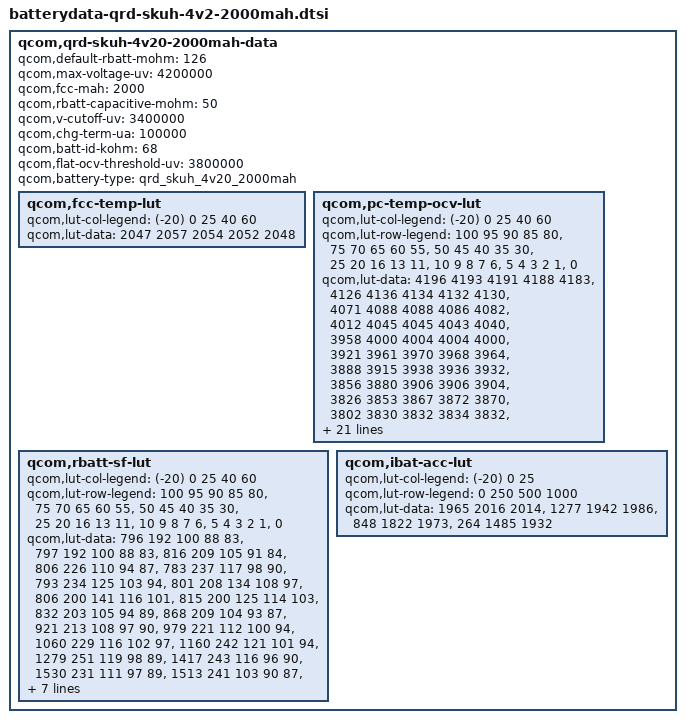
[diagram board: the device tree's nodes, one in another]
/* Copyright (c) 2014, The Linux Foundation. All rights reserved.
 *
 * This program is free software; you can redistribute it and/or modify
 * it under the terms of the GNU General Public License version 2 and
 * only version 2 as published by the Free Software Foundation.
 *
 * This program is distributed in the hope that it will be useful,
 * but WITHOUT ANY WARRANTY; without even the implied warranty of
 * MERCHANTABILITY or FITNESS FOR A PARTICULAR PURPOSE.  See the
 * GNU General Public License for more details.
 */

qcom,qrd-skuh-4v20-2000mah-data {
	qcom,default-rbatt-mohm = <126>;
	qcom,max-voltage-uv = <4200000>;
	qcom,fcc-mah = <2000>;
	qcom,rbatt-capacitive-mohm = <50>;
	qcom,v-cutoff-uv = <3400000>;
	qcom,chg-term-ua = <100000>;
	qcom,batt-id-kohm = <68>;
	qcom,flat-ocv-threshold-uv = <3800000>;
	qcom,battery-type = "qrd_skuh_4v20_2000mah";

	qcom,fcc-temp-lut {
		qcom,lut-col-legend = <(-20) 0 25 40 60>;
		qcom,lut-data = <2047 2057 2054 2052 2048>;
	};

	qcom,pc-temp-ocv-lut {
		qcom,lut-col-legend = <(-20) 0 25 40 60>;
		qcom,lut-row-legend = <100 95 90 85 80>,
				<75 70 65 60 55>,
				<50 45 40 35 30>,
				<25 20 16 13 11>,
				<10 9 8 7 6>,
				<5 4 3 2 1>,
				<0>;
		qcom,lut-data = <4196 4193 4191 4188 4183>,
				<4126 4136 4134 4132 4130>,
				<4071 4088 4088 4086 4082>,
				<4012 4045 4045 4043 4040>,
				<3958 4000 4004 4004 4000>,
				<3921 3961 3970 3968 3964>,
				<3888 3915 3938 3936 3932>,
				<3856 3880 3906 3906 3904>,
				<3826 3853 3867 3872 3870>,
				<3802 3830 3832 3834 3832>,
				<3784 3811 3812 3812 3810>,
				<3771 3795 3796 3796 3794>,
				<3758 3782 3783 3782 3780>,
				<3746 3773 3773 3771 3768>,
				<3734 3766 3766 3760 3752>,
				<3722 3752 3755 3746 3732>,
				<3708 3729 3734 3724 3710>,
				<3692 3706 3705 3696 3683>,
				<3675 3696 3684 3676 3664>,
				<3658 3691 3681 3673 3661>,
				<3645 3688 3679 3672 3660>,
				<3626 3685 3678 3670 3658>,
				<3603 3681 3675 3668 3655>,
				<3574 3676 3672 3662 3650>,
				<3534 3664 3662 3651 3637>,
				<3476 3638 3636 3622 3604>,
				<3398 3593 3589 3574 3552>,
				<3304 3528 3525 3510 3488>,
				<3230 3436 3439 3424 3400>,
				<3168 3295 3310 3292 3260>,
				<3000 3015 3000 3000 3000>;
	};

	qcom,rbatt-sf-lut {
		qcom,lut-col-legend = <(-20) 0 25 40 60>;
		qcom,lut-row-legend = <100 95 90 85 80>,
				<75 70 65 60 55>,
				<50 45 40 35 30>,
				<25 20 16 13 11>,
				<10 9 8 7 6>,
				<5 4 3 2 1>,
				<0>;
		qcom,lut-data = <796 192 100 88 83>,
				<797 192 100 88 83>,
				<816 209 105 91 84>,
				<806 226 110 94 87>,
				<783 237 117 98 90>,
				<793 234 125 103 94>,
				<801 208 134 108 97>,
				<806 200 141 116 101>,
				<815 200 125 114 103>,
				<832 203 105 94 89>,
				<868 209 104 93 87>,
				<921 213 108 97 90>,
				<979 221 112 100 94>,
				<1060 229 116 102 97>,
				<1160 242 121 101 94>,
				<1279 251 119 98 89>,
				<1417 243 116 96 90>,
				<1530 231 111 97 89>,
				<1513 241 103 90 87>,
				<1517 251 106 95 90>,
				<1602 262 110 98 91>,
				<1684 277 115 100 92>,
				<1797 296 122 103 94>,
				<1985 318 126 106 95>,
				<2363 341 129 105 94>,
				<3149 363 125 102 91>,
				<6298 402 123 102 92>,
				<12597 481 127 106 98>,
				<25194 646 143 121 109>,
				<50387 1292 190 156 168>,
				<100775 2584 379 311 337>;
	};

	qcom,ibat-acc-lut {
		qcom,lut-col-legend = <(-20) 0 25>;
		qcom,lut-row-legend = <0 250 500 1000>;
		qcom,lut-data = <1965 2016 2014>,
				<1277 1942 1986>,
				<848 1822 1973>,
				<264 1485 1932>;
	};
};
